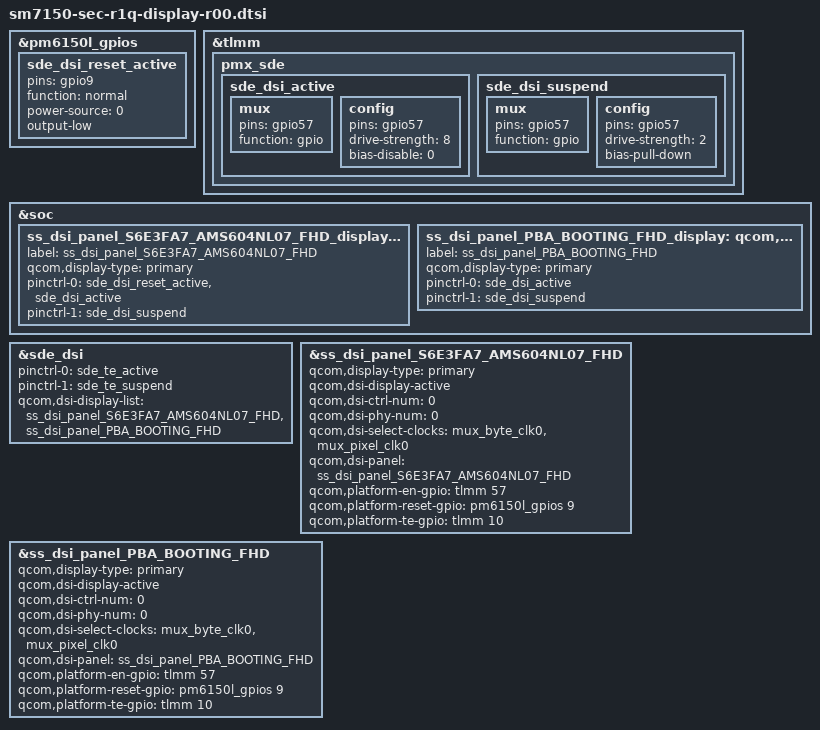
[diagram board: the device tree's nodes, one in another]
/* Copyright (c) 2016-2017, The Linux Foundation. All rights reserved.
 *
 * This program is free software; you can redistribute it and/or modify
 * it under the terms of the GNU General Public License version 2 and
 * only version 2 as published by the Free Software Foundation.
 *
 * This program is distributed in the hope that it will be useful,
 * but WITHOUT ANY WARRANTY; without even the implied warranty of
 * MERCHANTABILITY or FITNESS FOR A PARTICULAR PURPOSE.  See the
 * GNU General Public License for more details.
 */

#include "../../../../../drivers/gpu/drm/msm/samsung/SELF_DISPLAY/self_display_cmd_FA7_AMS604NL07.dtsi"
#include "../../../../../drivers/gpu/drm/msm/samsung/S6E3FA7_AMS604NL07/dsi_panel_S6E3FA7_AMS604NL07_fhd_octa_cmd.dtsi"
#include "../../../../../drivers/gpu/drm/msm/samsung/PBA_BOOTING/dsi_panel_PBA_BOOTING_fhd_video.dtsi"


#if 0
/{
	aliases {
		spi7 = &qupv3_se7_spi;
	};
};
#endif

&pm6150l_gpios {
	sde_dsi_reset_active: sde_dsi_reset_active {
		pins = "gpio9";
		function = "normal";
		power-source = <0>;
		output-low;
	};
};

&tlmm {
	pmx_sde: pmx_sde {
		sde_dsi_active: sde_dsi_active {
			mux {
				pins = "gpio57";
				function = "gpio";
			};

			config {
				pins = "gpio57";
				drive-strength = <8>;   /* 8 mA */
				bias-disable = <0>;   /* no pull */
			};
		};
		sde_dsi_suspend: sde_dsi_suspend {
			mux {
				pins = "gpio57";
				function = "gpio";
			};

			config {
				pins = "gpio57";
				drive-strength = <2>;   /* 2 mA */
				bias-pull-down;         /* PULL DOWN */
			};
		};
	};

	/delete-node/ pmx_sde_te;
#if 0
	pmx_sde_te {
		sde_te_active: sde_te_active {
			mux {
				pins = "gpio10";
				function = "mdp_vsync";
			};

			config {
				pins = "gpio10";
				drive-strength = <2>;   /* 2 mA */
				bias-pull-down;         /* PULL DOWN */
			};
		};

		sde_te_suspend: sde_te_suspend {
			mux {
				pins = "gpio10";
				function = "mdp_vsync";
			};

			config {
				pins = "gpio10";
				drive-strength = <2>;   /* 2 mA */
				bias-pull-down;         /* PULL DOWN */
			};
		};
	};
#endif
};


&soc {
	/* A50 panel */
	ss_dsi_panel_S6E3FA7_AMS604NL07_FHD_display: qcom,dsi-display@9 {
		label = "ss_dsi_panel_S6E3FA7_AMS604NL07_FHD";
		qcom,display-type = "primary";

		pinctrl-names = "panel_active", "panel_suspend";
#if 0
		pinctrl-0 = <&sde_dsi_reset_active &sde_dsi_active &sde_te_active>;
		pinctrl-1 = <&sde_dsi_suspend &sde_te_suspend>;
#endif
		pinctrl-0 = <&sde_dsi_reset_active &sde_dsi_active>;
		pinctrl-1 = <&sde_dsi_suspend>;
	};

	/* PBA */
	ss_dsi_panel_PBA_BOOTING_FHD_display: qcom,dsi-display@10 {
		label = "ss_dsi_panel_PBA_BOOTING_FHD";
		qcom,display-type = "primary";

		pinctrl-names = "panel_active", "panel_suspend";
		pinctrl-0 = <&sde_dsi_active>;
		pinctrl-1 = <&sde_dsi_suspend>;
	};
};

&sde_dsi {
	pinctrl-names = "panel_active", "panel_suspend";
	pinctrl-0 = <&sde_te_active>;
	pinctrl-1 = <&sde_te_suspend>;
	qcom,dsi-display-list =
		<&ss_dsi_panel_S6E3FA7_AMS604NL07_FHD
		&ss_dsi_panel_PBA_BOOTING_FHD>;
};


&ss_dsi_panel_S6E3FA7_AMS604NL07_FHD {
	qcom,display-type = "primary";
	qcom,dsi-display-active;

	qcom,dsi-ctrl-num = <0>;
	qcom,dsi-phy-num = <0>;
	qcom,dsi-select-clocks = "mux_byte_clk0", "mux_pixel_clk0";

	qcom,dsi-panel = <&ss_dsi_panel_S6E3FA7_AMS604NL07_FHD>;

	qcom,platform-en-gpio = <&tlmm 57 0>;
	qcom,platform-reset-gpio = <&pm6150l_gpios 9 0>;
	qcom,platform-te-gpio = <&tlmm 10 0>;
};

&ss_dsi_panel_PBA_BOOTING_FHD {
	qcom,display-type = "primary";
	qcom,dsi-display-active;

	qcom,dsi-ctrl-num = <0>;
	qcom,dsi-phy-num = <0>;
	qcom,dsi-select-clocks = "mux_byte_clk0", "mux_pixel_clk0";

	qcom,dsi-panel = <&ss_dsi_panel_PBA_BOOTING_FHD>;

	qcom,platform-en-gpio = <&tlmm 57 0>;
	qcom,platform-reset-gpio = <&pm6150l_gpios 9 0>;
	qcom,platform-te-gpio = <&tlmm 10 0>;
};

